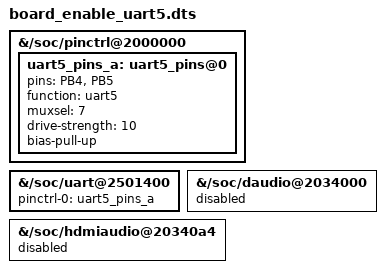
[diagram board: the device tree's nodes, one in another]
/dts-v1/;
/plugin/;

/*
/include/ "sun20iw1p1.dtsi"
/include/ "board.dts"
*/

/ {

	fragment@0 {
		target-path = "/soc/pinctrl@2000000";

		__overlay__ {
			uart5_pins_a : uart5_pins@0 {
				pins = "PB4", "PB5";
				function = "uart5";
				muxsel = <7>;
				drive-strength = <10>;
				bias-pull-up;
			};
		};
	};

	fragment@1 {
		target-path = "/soc/uart@2501400";

		__overlay__ {
			pinctrl-names = "default";
			pinctrl-0 = <&uart5_pins_a>;
			status = "okay";
		};
	};

	fragment@2 {
		target-path = "/soc/daudio@2034000";

		__overlay__ {
			status = "disabled";
		};
	};

	fragment@3 {
		target-path = "/soc/hdmiaudio@20340a4";

		__overlay__ {
			status = "disabled"; /* if HDMI audio is used, daudio2 should be enable. */
		};
	};
};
